AUTOSAR XML (schema 00048)
package /AUTOLIV/SoftwareComponents/HWA
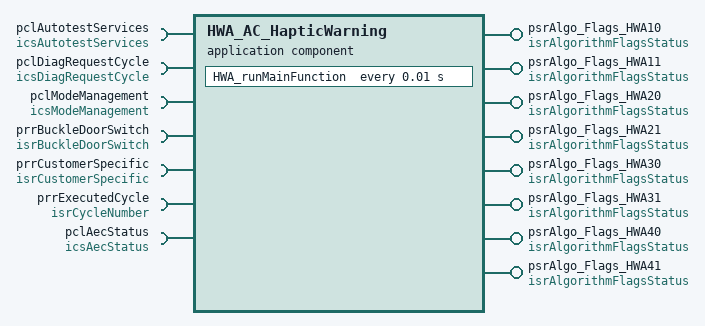
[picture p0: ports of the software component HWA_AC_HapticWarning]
  application sw component type HWA_AC_HapticWarning
    6 x require port:
      pclAutotestServices: required-com-specs=[GetLastCriticalAutotestID, GetTestResult], required-interface=icsAutotestServices
      pclDiagRequestCycle: required-com-specs=[ClearDiagRequestCycle, GetDiagRequestCycle], required-interface=icsDiagRequestCycle
      pclModeManagement: client-com-spec=CheckModeStatus, required-interface=icsModeManagement
      prrBuckleDoorSwitch: required-interface=isrBuckleDoorSwitch
        required-com-specs:
          data-element=u8BuckleSwitch, init-value=constant-reference=APPLINIT_KB8_BUCKLE_SWITCH_CLOSED
          data-element=u8DoorSwitch, init-value=constant-reference=APPLINIT_KU8_DOOR_SWITCH_STATUS_NOT_DEFINED
      prrCustomerSpecific: required-interface=isrCustomerSpecific
        required-com-specs:
          data-element=b8HardReleaseRequest
          data-element=b8IsCarCrankingActive, init-value=constant-reference=APPLINIT_KB8_CAR_CRANKING_ACTIVE_TRUE
          data-element=b8IsCarCrashDetected, init-value=constant-reference=APPLINIT_KB8_CAR_CRASH_DETECTED_FALSE
          data-element=b8IsTrigOffEventAllowed
          data-element=b8PreCrashRequestEnable, init-value=constant-reference=APPLINIT_KB8_BOOLEAN_FALSE
          data-element=u8BeltSlackStatus, init-value=constant-reference=APPLINIT_KU8_BELT_SLACK_STATUS_NOT_DEFINED
          data-element=u8HapticRequest, init-value=constant-reference=APPLINIT_KU8_HAPTIC_REQUEST_NO
          data-element=u8PreCrashRequest, init-value=constant-reference=APPLINIT_KU8_PRE_CRASH_REQUEST_NO_REQUEST
          data-element=u8TriggerRequest
          data-element=b8SignalRelInhibition
      prrExecutedCycle: nonqueued-receiver-com-spec{data-element=u8CycleNumber, init-value=constant-reference=APPLINIT_KU8_CYCLE_NUMBER_NONE}, required-interface=isrCycleNumber
    provide port psrAlgo_Flags_HWA10: provided-interface=isrAlgorithmFlagsStatus
      provided-com-specs:
        data-element=b8InterruptFlag, init-value=constant-reference=APPLINIT_KB8_ALGO_FLAG_FALSE
        data-element=b8PreActivationFlag, init-value=constant-reference=APPLINIT_KB8_ALGO_FLAG_FALSE
        data-element=b8PreConditionsFlag, init-value=constant-reference=APPLINIT_KB8_ALGO_FLAG_FALSE
        data-element=b8TriggerFlag, init-value=constant-reference=APPLINIT_KB8_ALGO_FLAG_FALSE
        data-element=u8TriggeringSource, init-value=constant-reference=APPLINIT_KU8_TRIGGERING_SOURCE_NO
    provide port psrAlgo_Flags_HWA11: provided-interface=isrAlgorithmFlagsStatus
      provided-com-specs:
        data-element=b8InterruptFlag, init-value=constant-reference=APPLINIT_KB8_ALGO_FLAG_FALSE
        data-element=b8PreActivationFlag, init-value=constant-reference=APPLINIT_KB8_ALGO_FLAG_FALSE
        data-element=b8PreConditionsFlag, init-value=constant-reference=APPLINIT_KB8_ALGO_FLAG_FALSE
        data-element=b8TriggerFlag, init-value=constant-reference=APPLINIT_KB8_ALGO_FLAG_FALSE
        data-element=u8TriggeringSource, init-value=constant-reference=APPLINIT_KU8_TRIGGERING_SOURCE_NO
    require port pclAecStatus: required-interface=icsAecStatus
      required-com-specs:
        SetAecEvent
        GetNumberOfImplementedAec
        GetAecStatus
        GetAecQualificationCount
        GetAecNvpBlockRecordingStatus
        GetAecGroupsStatus
        GetAecDeskillThrs
    6 x provide port, all with provided-interface=isrAlgorithmFlagsStatus:
      psrAlgo_Flags_HWA20
        provided-com-specs:
          data-element=b8InterruptFlag, init-value=constant-reference=APPLINIT_KB8_ALGO_FLAG_FALSE
          data-element=b8PreActivationFlag, init-value=constant-reference=APPLINIT_KB8_ALGO_FLAG_FALSE
          data-element=b8PreConditionsFlag, init-value=constant-reference=APPLINIT_KB8_ALGO_FLAG_FALSE
          data-element=b8TriggerFlag, init-value=constant-reference=APPLINIT_KB8_ALGO_FLAG_FALSE
          data-element=u8TriggeringSource, init-value=constant-reference=APPLINIT_KU8_TRIGGERING_SOURCE_NO
      psrAlgo_Flags_HWA21
        provided-com-specs:
          data-element=b8InterruptFlag, init-value=constant-reference=APPLINIT_KB8_ALGO_FLAG_FALSE
          data-element=b8PreActivationFlag, init-value=constant-reference=APPLINIT_KB8_ALGO_FLAG_FALSE
          data-element=b8PreConditionsFlag, init-value=constant-reference=APPLINIT_KB8_ALGO_FLAG_FALSE
          data-element=b8TriggerFlag, init-value=constant-reference=APPLINIT_KB8_ALGO_FLAG_FALSE
          data-element=u8TriggeringSource, init-value=constant-reference=APPLINIT_KU8_TRIGGERING_SOURCE_NO
      psrAlgo_Flags_HWA30
        provided-com-specs:
          data-element=b8InterruptFlag, init-value=constant-reference=APPLINIT_KB8_ALGO_FLAG_FALSE
          data-element=b8PreActivationFlag, init-value=constant-reference=APPLINIT_KB8_ALGO_FLAG_FALSE
          data-element=b8PreConditionsFlag, init-value=constant-reference=APPLINIT_KB8_ALGO_FLAG_FALSE
          data-element=b8TriggerFlag, init-value=constant-reference=APPLINIT_KB8_ALGO_FLAG_FALSE
          data-element=u8TriggeringSource, init-value=constant-reference=APPLINIT_KU8_TRIGGERING_SOURCE_NO
      psrAlgo_Flags_HWA31
        provided-com-specs:
          data-element=b8InterruptFlag, init-value=constant-reference=APPLINIT_KB8_ALGO_FLAG_FALSE
          data-element=b8PreActivationFlag, init-value=constant-reference=APPLINIT_KB8_ALGO_FLAG_FALSE
          data-element=b8PreConditionsFlag, init-value=constant-reference=APPLINIT_KB8_ALGO_FLAG_FALSE
          data-element=b8TriggerFlag, init-value=constant-reference=APPLINIT_KB8_ALGO_FLAG_FALSE
          data-element=u8TriggeringSource, init-value=constant-reference=APPLINIT_KU8_TRIGGERING_SOURCE_NO
      psrAlgo_Flags_HWA40
        provided-com-specs:
          data-element=b8InterruptFlag, init-value=constant-reference=APPLINIT_KB8_ALGO_FLAG_FALSE
          data-element=b8PreActivationFlag, init-value=constant-reference=APPLINIT_KB8_ALGO_FLAG_FALSE
          data-element=b8PreConditionsFlag, init-value=constant-reference=APPLINIT_KB8_ALGO_FLAG_FALSE
          data-element=b8TriggerFlag, init-value=constant-reference=APPLINIT_KB8_ALGO_FLAG_FALSE
          data-element=u8TriggeringSource, init-value=constant-reference=APPLINIT_KU8_TRIGGERING_SOURCE_NO
      psrAlgo_Flags_HWA41
        provided-com-specs:
          data-element=b8InterruptFlag, init-value=constant-reference=APPLINIT_KB8_ALGO_FLAG_FALSE
          data-element=b8PreActivationFlag, init-value=constant-reference=APPLINIT_KB8_ALGO_FLAG_FALSE
          data-element=b8PreConditionsFlag, init-value=constant-reference=APPLINIT_KB8_ALGO_FLAG_FALSE
          data-element=b8TriggerFlag, init-value=constant-reference=APPLINIT_KB8_ALGO_FLAG_FALSE
          data-element=u8TriggeringSource, init-value=constant-reference=APPLINIT_KU8_TRIGGERING_SOURCE_NO
    behavior HWA_IB_HapticWarning: data-type-mapping=DataTypeMappingSet_PP4G
      timing event HWA_evMainFunction: start-on-event=HWA_runMainFunction, period=0.01
      runnable HWA_runMainFunction
        data-receive-point-by-arguments:
          5 x access:
            DRP_prrBuckleDoorSwitch_u8BuckleSwitch: accessed-variable=prrBuckleDoorSwitch.u8BuckleSwitch
            DRP_prrCustomerSpecific_b8IsCarCrankingActive: accessed-variable=prrCustomerSpecific.b8IsCarCrankingActive
            DRP_prrCustomerSpecific_b8IsCarCrashDetected: accessed-variable=prrCustomerSpecific.b8IsCarCrashDetected
            DRP_prrCustomerSpecific_u8HapticRequest: accessed-variable=prrCustomerSpecific.u8HapticRequest
            DRP_prrExecutedCycle_u8CycleNumber: accessed-variable=prrExecutedCycle.u8CycleNumber
        data-send-points:
          40 x access:
            DSP_psrAlgo_Flags_HWA0_b8InterruptFlag: accessed-variable=psrAlgo_Flags_HWA10.b8InterruptFlag
            DSP_psrAlgo_Flags_HWA0_b8PreActivationFlag: accessed-variable=psrAlgo_Flags_HWA10.b8PreActivationFlag
            DSP_psrAlgo_Flags_HWA0_b8PreConditionsFlag: accessed-variable=psrAlgo_Flags_HWA10.b8PreConditionsFlag
            DSP_psrAlgo_Flags_HWA0_b8TriggerFlag: accessed-variable=psrAlgo_Flags_HWA10.b8TriggerFlag
            DSP_psrAlgo_Flags_HWA0_u8TriggeringSource: accessed-variable=psrAlgo_Flags_HWA10.u8TriggeringSource
            DSP_psrAlgo_Flags_HWA1_b8InterruptFlag: accessed-variable=psrAlgo_Flags_HWA11.b8InterruptFlag
            DSP_psrAlgo_Flags_HWA1_b8PreActivationFlag: accessed-variable=psrAlgo_Flags_HWA11.b8PreActivationFlag
            DSP_psrAlgo_Flags_HWA1_b8PreConditionsFlag: accessed-variable=psrAlgo_Flags_HWA11.b8PreConditionsFlag
            DSP_psrAlgo_Flags_HWA1_b8TriggerFlag: accessed-variable=psrAlgo_Flags_HWA11.b8TriggerFlag
            DSP_psrAlgo_Flags_HWA1_u8TriggeringSource: accessed-variable=psrAlgo_Flags_HWA11.u8TriggeringSource
            SEND_psrAlgo_Flags_HWA20_b8InterruptFlag: accessed-variable=psrAlgo_Flags_HWA20.b8InterruptFlag
            SEND_psrAlgo_Flags_HWA20_b8PreActivationFlag: accessed-variable=psrAlgo_Flags_HWA20.b8PreActivationFlag
            SEND_psrAlgo_Flags_HWA20_b8PreConditionsFlag: accessed-variable=psrAlgo_Flags_HWA20.b8PreConditionsFlag
            SEND_psrAlgo_Flags_HWA20_b8TriggerFlag: accessed-variable=psrAlgo_Flags_HWA20.b8TriggerFlag
            SEND_psrAlgo_Flags_HWA20_u8TriggeringSource: accessed-variable=psrAlgo_Flags_HWA20.u8TriggeringSource
            SEND_psrAlgo_Flags_HWA21_b8InterruptFlag: accessed-variable=psrAlgo_Flags_HWA21.b8InterruptFlag
            SEND_psrAlgo_Flags_HWA21_b8PreActivationFlag: accessed-variable=psrAlgo_Flags_HWA21.b8PreActivationFlag
            SEND_psrAlgo_Flags_HWA21_b8PreConditionsFlag: accessed-variable=psrAlgo_Flags_HWA21.b8PreConditionsFlag
            SEND_psrAlgo_Flags_HWA21_b8TriggerFlag: accessed-variable=psrAlgo_Flags_HWA21.b8TriggerFlag
            SEND_psrAlgo_Flags_HWA21_u8TriggeringSource: accessed-variable=psrAlgo_Flags_HWA21.u8TriggeringSource
            SEND_psrAlgo_Flags_HWA30_b8InterruptFlag: accessed-variable=psrAlgo_Flags_HWA30.b8InterruptFlag
            SEND_psrAlgo_Flags_HWA30_b8PreActivationFlag: accessed-variable=psrAlgo_Flags_HWA30.b8PreActivationFlag
            SEND_psrAlgo_Flags_HWA30_b8PreConditionsFlag: accessed-variable=psrAlgo_Flags_HWA30.b8PreConditionsFlag
            SEND_psrAlgo_Flags_HWA30_b8TriggerFlag: accessed-variable=psrAlgo_Flags_HWA30.b8TriggerFlag
            SEND_psrAlgo_Flags_HWA30_u8TriggeringSource: accessed-variable=psrAlgo_Flags_HWA30.u8TriggeringSource
            SEND_psrAlgo_Flags_HWA31_b8InterruptFlag: accessed-variable=psrAlgo_Flags_HWA31.b8InterruptFlag
            SEND_psrAlgo_Flags_HWA31_b8PreActivationFlag: accessed-variable=psrAlgo_Flags_HWA31.b8PreActivationFlag
            SEND_psrAlgo_Flags_HWA31_b8PreConditionsFlag: accessed-variable=psrAlgo_Flags_HWA31.b8PreConditionsFlag
            SEND_psrAlgo_Flags_HWA31_b8TriggerFlag: accessed-variable=psrAlgo_Flags_HWA31.b8TriggerFlag
            SEND_psrAlgo_Flags_HWA31_u8TriggeringSource: accessed-variable=psrAlgo_Flags_HWA31.u8TriggeringSource
            SEND_psrAlgo_Flags_HWA40_b8InterruptFlag: accessed-variable=psrAlgo_Flags_HWA40.b8InterruptFlag
            SEND_psrAlgo_Flags_HWA40_b8PreActivationFlag: accessed-variable=psrAlgo_Flags_HWA40.b8PreActivationFlag
            SEND_psrAlgo_Flags_HWA40_b8PreConditionsFlag: accessed-variable=psrAlgo_Flags_HWA40.b8PreConditionsFlag
            SEND_psrAlgo_Flags_HWA40_b8TriggerFlag: accessed-variable=psrAlgo_Flags_HWA40.b8TriggerFlag
            SEND_psrAlgo_Flags_HWA40_u8TriggeringSource: accessed-variable=psrAlgo_Flags_HWA40.u8TriggeringSource
            SEND_psrAlgo_Flags_HWA41_b8InterruptFlag: accessed-variable=psrAlgo_Flags_HWA41.b8InterruptFlag
            SEND_psrAlgo_Flags_HWA41_b8PreActivationFlag: accessed-variable=psrAlgo_Flags_HWA41.b8PreActivationFlag
            SEND_psrAlgo_Flags_HWA41_b8PreConditionsFlag: accessed-variable=psrAlgo_Flags_HWA41.b8PreConditionsFlag
            SEND_psrAlgo_Flags_HWA41_b8TriggerFlag: accessed-variable=psrAlgo_Flags_HWA41.b8TriggerFlag
            SEND_psrAlgo_Flags_HWA41_u8TriggeringSource: accessed-variable=psrAlgo_Flags_HWA41.u8TriggeringSource
        5 x sync call:
          SSCP_pclDiagRequestCycle_ClearDiagRequestCycle: operation=pclDiagRequestCycle.ClearDiagRequestCycle
          SSCP_pclDiagRequestCycle_GetDiagRequestCycle: operation=pclDiagRequestCycle.GetDiagRequestCycle
          SSCP_pclModeManagement_CheckModeStatus: operation=pclModeManagement.CheckModeStatus
          SSCP_pclTestResult_GetTestResult: operation=pclAutotestServices.GetTestResult
          SC_pclAecStatus_GetAecStatus: operation=pclAecStatus.GetAecStatus
  swc implementation HWA_AC_HapticWarning_Implementation: behavior=HWA_IB_HapticWarning
